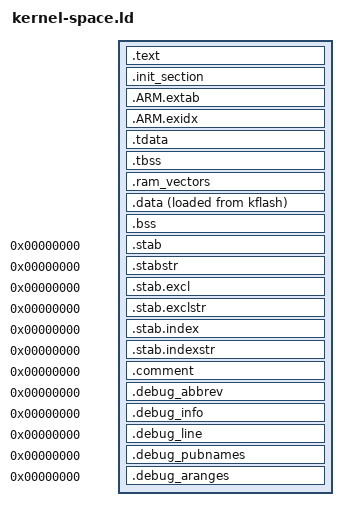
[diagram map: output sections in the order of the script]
/****************************************************************************
 * boards/arm/mps/mps2-an521/scripts/kernel-space.ld
 *
 * SPDX-License-Identifier: Apache-2.0
 *
 * Licensed to the Apache Software Foundation (ASF) under one or more
 * contributor license agreements.  See the NOTICE file distributed with
 * this work for additional information regarding copyright ownership.  The
 * ASF licenses this file to you under the Apache License, Version 2.0 (the
 * "License"); you may not use this file except in compliance with the
 * License.  You may obtain a copy of the License at
 *
 *   http://www.apache.org/licenses/LICENSE-2.0
 *
 * Unless required by applicable law or agreed to in writing, software
 * distributed under the License is distributed on an "AS IS" BASIS, WITHOUT
 * WARRANTIES OR CONDITIONS OF ANY KIND, either express or implied.  See the
 * License for the specific language governing permissions and limitations
 * under the License.
 *
 ****************************************************************************/

/* The BUILD_PROTECTED kernel blob.
 *
 * NOTE:  This depends on the memory.ld script having been included prior to
 * this script; that file defines kflash/ksram and this one places sections
 * into them.
 *
 * This is flash.ld -- the flat script -- with its own MEMORY block removed and
 * flash/sram1 retargeted to kflash/ksram.  Unlike mps3-an547, which can link
 * its kernel with flash.ld unchanged because its user blob lives in entirely
 * different banks, the AN521 has only two banks and both halves come out of
 * them, so the kernel needs a script that stops at the halfway mark.
 *
 * The user blob is linked separately, against memory.ld + user-space.ld.
 */

OUTPUT_ARCH(arm)
EXTERN(_vectors)
ENTRY(__start)

SECTIONS
{
    .text : {
        _stext = ABSOLUTE(.);
        *(.vectors)
        *(.text .text.*)
        *(.fixup)
        *(.gnu.warning)
        *(.rodata .rodata.*)
        *(.gnu.linkonce.t.*)
        *(.glue_7)
        *(.glue_7t)
        *(.got)
        *(.gcc_except_table)
        *(.gnu.linkonce.r.*)
        _etext = ABSOLUTE(.);
    } > kflash

    .init_section : ALIGN(4) {
        _sinit = ABSOLUTE(.);
        KEEP(*(SORT_BY_INIT_PRIORITY(.init_array.*) SORT_BY_INIT_PRIORITY(.ctors.*)))
        KEEP(*(.init_array EXCLUDE_FILE(*crtbegin.o *crtbegin?.o *crtend.o *crtend?.o) .ctors))
        _einit = ABSOLUTE(.);
    } > kflash

    .ARM.extab : ALIGN(4) {
        *(.ARM.extab*)
    } > kflash

    .ARM.exidx : ALIGN(4) {
        __exidx_start = ABSOLUTE(.);
        *(.ARM.exidx*)
        __exidx_end = ABSOLUTE(.);
    } > kflash

    .tdata : {
        _stdata = ABSOLUTE(.);
        *(.tdata .tdata.* .gnu.linkonce.td.*);
        _etdata = ABSOLUTE(.);
    } > kflash

    .tbss : {
        _stbss = ABSOLUTE(.);
        *(.tbss .tbss.* .gnu.linkonce.tb.* .tcommon);
        _etbss = ABSOLUTE(.);
    } > kflash

    _eronly = ABSOLUTE(.);

    /* The RAM vector table (if present) should lie at the beginning of SRAM */

    .ram_vectors : {
        *(.ram_vectors)
    } > ksram

    .data : ALIGN(4) {
        _sdata = ABSOLUTE(.);
        *(.data .data.*)
        *(.gnu.linkonce.d.*)
        CONSTRUCTORS
        . = ALIGN(4);
        _edata = ABSOLUTE(.);
    } > ksram AT > kflash

    .bss : ALIGN(4) {
        _sbss = ABSOLUTE(.);
        *(.bss .bss.*)
        *(.gnu.linkonce.b.*)
        *(COMMON)
        . = ALIGN(4);
        _ebss = ABSOLUTE(.);
    } > ksram

    /* Stabs debugging sections. */

    .stab 0 : { *(.stab) }
    .stabstr 0 : { *(.stabstr) }
    .stab.excl 0 : { *(.stab.excl) }
    .stab.exclstr 0 : { *(.stab.exclstr) }
    .stab.index 0 : { *(.stab.index) }
    .stab.indexstr 0 : { *(.stab.indexstr) }
    .comment 0 : { *(.comment) }
    .debug_abbrev 0 : { *(.debug_abbrev) }
    .debug_info 0 : { *(.debug_info) }
    .debug_line 0 : { *(.debug_line) }
    .debug_pubnames 0 : { *(.debug_pubnames) }
    .debug_aranges 0 : { *(.debug_aranges) }
}
